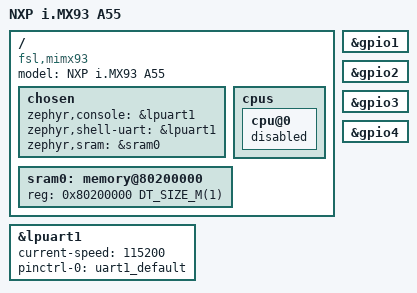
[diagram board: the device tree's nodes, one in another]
/*
 * Copyright 2022 NXP
 *
 * SPDX-License-Identifier: Apache-2.0
 */

/dts-v1/;

#include <nxp/nxp_mimx93_a55.dtsi>
#include "mimx93_evk-pinctrl.dtsi"

/ {
	model = "NXP i.MX93 A55";
	compatible = "fsl,mimx93";

	chosen {
		zephyr,console = &lpuart1;
		zephyr,shell-uart = &lpuart1;
		zephyr,sram = &sram0;
	};

	cpus {
		cpu@0 {
			status = "disabled";
		};
	};

	sram0: memory@80200000 {
		reg = <0x80200000 DT_SIZE_M(1)>;
	};
};

&lpuart1 {
	status = "okay";
	current-speed = <115200>;
	pinctrl-0 = <&uart1_default>;
	pinctrl-names = "default";
};

&gpio1{
    status = "okay";
};

&gpio2{
    status = "okay";
};

&gpio3{
    status = "okay";
};

&gpio4{
    status = "okay";
};
